# M55M1 register map
File version: 1.0
Registers are 32-bit, read-write, reset 0x0 unless marked. A register's access mark holds for its fields unless they carry their own. Offsets are from the block's base; [hi:lo] are bit positions; {n}, {i} and the like mark numbered series.

## EBI_NS — EBI Register Map
Base 0x50230000
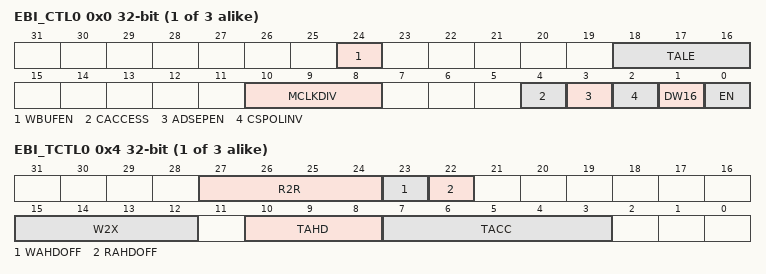
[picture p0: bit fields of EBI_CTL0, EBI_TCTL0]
{0x0+0x10*i} EBI_CTL{i} (i=0..2) — External Bus Interface Bank{i} Control Register
  [24] WBUFEN — EBI Write Buffer Enable Bit. Note: This bit is only available in EBI_CTL0 register. (Write buffer enable of bank0~2 are controlled by this bit)
    0=EBI write buffer Disabled; 1=EBI write buffer Enabled
  [18:16] TALE — Extend Time of ALE. The EBI_ALE high pulse period (tALE) to latch the address can be controlled by TALE. Note: This field is only available in EBI_CTL0 register. (Extend time of ALE of bank0~2 are controlled by these bits)
  [10:8] MCLKDIV — External Output Clock Divider. The frequency of EBI output clock (MCLK) is controlled by MCLKDIV as follow:
    0=HCLK/1; 1=HCLK/2; 2=HCLK/4; 3=HCLK/8; 4=HCLK/16; 5=HCLK/32; 6=HCLK/64; 7=HCLK/128
  [4] CACCESS — Continuous Data Access Mode. When continuous access mode enabled, the tASU, tALE and tLHD cycles are bypass for continuous data transfer request.
    0=Continuous data access mode Disabled; 1=Continuous data access mode Enabled
  [3] ADSEPEN — EBI Address/Data Bus Separate Mode Enable Bit
    0=Address/Data Bus Separate Mode Disabled; 1=Address/Data Bus Separate Mode Enabled
  [2] CSPOLINV — Chip Select Pin Polar Inverse. This bit defines the active level of EBI chip select pin (EBI_nCS).
    0=Chip select pin (EBI_nCS) is active low; 1=Chip select pin (EBI_nCS) is active high
  [1] DW16 — EBI Data Width 16-bit Select. This bit defines if the EBI data width is 8-bit or 16-bit.
    0=EBI data width is 8-bit; 1=EBI data width is 16-bit
  [0] EN — EBI Enable Bit. This bit is the functional enable bit for EBI.
    0=EBI function Disabled; 1=EBI function Enabled
{0x4+0x10*i} EBI_TCTL{i} (i=0..2) — External Bus Interface Bank{i} Timing Control Register
  [27:24] R2R — Idle Cycle Between Read-to-read. This field defines the number of R2R idle cycle. When read action is finished and the next action is going to read, R2R idle cycle is inserted and EBI_nCS return to idle state.
  [23] WAHDOFF — Access Hold Time Disable Control When Write
    0=Data Access Hold Time (tAHD) during EBI writing Enabled; 1=Data Access Hold Time (tAHD) during EBI writing Disabled
  [22] RAHDOFF — Access Hold Time Disable Control When Read
    0=Data Access Hold Time (tAHD) during EBI reading Enabled; 1=Data Access Hold Time (tAHD) during EBI reading Disabled
  [15:12] W2X — Idle Cycle After Write. This field defines the number of W2X idle cycle. When write action is finished, W2X idle cycle is inserted and EBI_nCS return to idle state.
  [10:8] TAHD — EBI Data Access Hold Time. TAHD defines data access hold time (tAHD).
  [7:3] TACC — EBI Data Access Time. TACC defines data access time (tACC).

## LPGPIO_NS — LPGPIO Register Map
Base 0x50403000
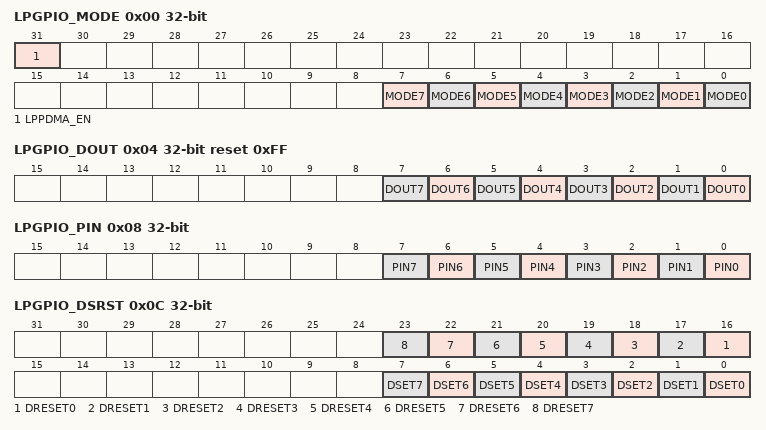
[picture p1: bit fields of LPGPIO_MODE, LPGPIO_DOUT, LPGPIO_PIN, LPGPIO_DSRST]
0x00 LPGPIO_MODE — LPIOn Mode Control
  [31] LPPDMA_EN — LPPDMA Enable Bit. This bit is used to enable LPPDMA to access LPGPIO when chip is in NPD0/1/3.
    0=LPPDMA can't access LPGPIO when chip is in NPD0/1/3; 1=LPPDMA can access LPGPIO when chip is in NPD0/1/3
  [n] MODE{n} (n=0..7) — LPIOn I/O Pin Mode Control. Determine each I/O mode of LPIOn pins.
    0=LPIOn is in Input mode; 1=LPIOn is in Push-pull Output mode
0x04 LPGPIO_DOUT reset 0xFF — LPIOn Data Output Value
  [all] fields
    0=LPIOn will drive Low if the LPIOn pin is configured as Push-pull output mode; 1=LPIOn will drive High if the LPIOn pin is configured as Push-pull output mode
  [n] DOUT{n} (n=0..7) — LPIOn Output Value. Each of these bits controls the status of a LPIOn pin when the LPIOn is configured as Push-pull output mode.
0x08 LPGPIO_PIN ro (reset mask 0xFFFFFF00) — LPIOn Pin Value
  [n] PIN{n} (n=0..7) — LPIOn Pin Value. Each bit of the register reflects the actual status of the respective Pn pin. If the bit is 1, it indicates the corresponding pin status is high; else the pin status is low.
0x0C LPGPIO_DSRST wo — LPIOn Data Output Set and Reset Control
  [n+16] DRESET{n} (n=0..7) — LPIOn Data Ouput Reset Control (Write Only). Writing 1 to each bit can reset LPIOn pin output data to 0. Note 1: This bit field is write only, reading this field will response with 0. Note 2: If DRESET[n] and DSET[n] are both set, DSET[n] has higher pirority. Note 3: Writing 1 to DRESET[n] will make DOUT[n] reflect the reset value.
    0=No action; 1=Reset LPIOn to 0
  [n] DSET{n} (n=0..7) — LPIOn Data Ouput Set Control (Write Only). Writing 1 to each bit can set LPIOn pin output data to 1. Note 1: This bit field is write only, reading this field will response with 0. Note 2: If DRESET[n] and DSET[n] are both set, DSET[n] has higher pirority. Note 3: Writing 1 to DSET[n] will make DOUT[n] reflect the set value.
    0=No action; 1=Reset LPIOn to 1
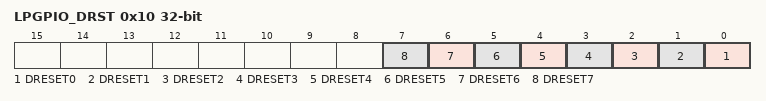
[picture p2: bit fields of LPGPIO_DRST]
0x10 LPGPIO_DRST wo — LPIOn Data Output Reset Control
  [all] fields
    0=No action; 1=Reset LPIOn to 0
  [n] DRESET{n} (n=0..7) — LPIOn Data Ouput Reset Control (Write Only). Writing 1 to each bit can reset LPIOn pin output data to 0. Note 1: This bit field is write only, reading this field will response with 0. Note 2: Writing 1 to DRESET[n] will make DOUT[n] reflect the reset value.
